# RSL15 register map
Vendor: ONSemiconductor; Series: RSL15 Series; File version: 1.0
CPU: CM33 r0p4, little endian, MPU, FPU, 3 interrupt priority bits
Registers are 32-bit, read-write, reset 0x0 unless marked. A register's access mark holds for its fields unless they carry their own. Offsets are from the block's base; [hi:lo] are bit positions; 'fields as' and 'values as' point back to an identical list.

## RF0 (part 2 of 3) — RF Front-End 2.4 GHz
Base 0x40040800
Same registers: RF1 0x40040A00, RF2 0x40040C00
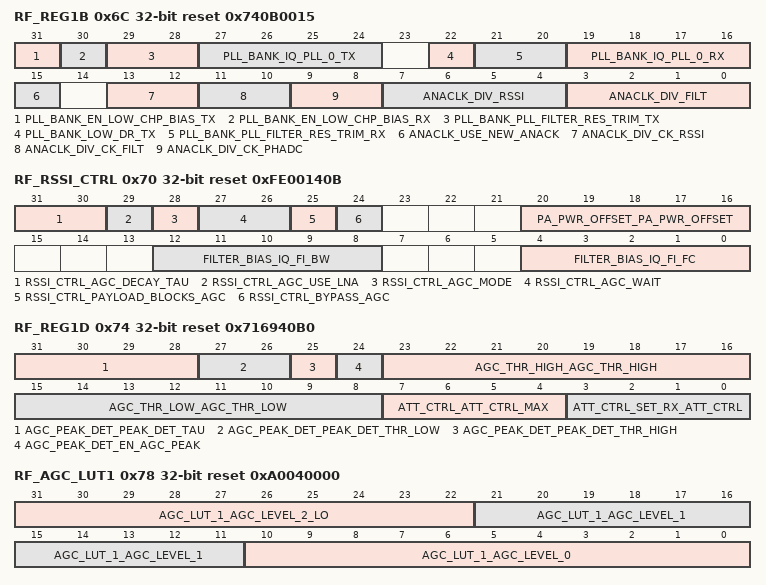
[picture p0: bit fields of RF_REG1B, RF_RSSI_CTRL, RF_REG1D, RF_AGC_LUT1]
0x6C RF_REG1B reset 0x740B0015 — REG1B
  [31] PLL_BANK_EN_LOW_CHP_BIAS_TX — Set the en_low_chp_bias bit in Tx mode (banked)
    0=PLL_BANK_EN_LOW_CHP_BIAS_TX_RESET (In Tx mode EN_LOW_CHP_BIAS bit is reset); 1=PLL_BANK_EN_LOW_CHP_BIAS_TX_SET (In Tx mode EN_LOW_CHP_BIAS bit is set)
  [30] PLL_BANK_EN_LOW_CHP_BIAS_RX — Set the en_low_chp_bias bit in Rx mode (banked)
    0=PLL_BANK_EN_LOW_CHP_BIAS_RX_RESET (In Rx mode EN_LOW_CHP_BIAS bit is reset); 1=PLL_BANK_EN_LOW_CHP_BIAS_RX_SET (In Rx mode EN_LOW_CHP_BIAS bit is set)
  [29:28] PLL_BANK_PLL_FILTER_RES_TRIM_TX — Modify the value of the loop filter resistor R2 when bit 5 is high in Tx mode (banked)
    0=Normal resistor; 1=Normal resistor + 23 percent; 2=Normal resistor + 30 percent; 3=Normal resistor + 70 percent
  [27:24] PLL_BANK_IQ_PLL_0_TX — Charge pump bias for Tx case (banked)
    4=PLL_BANK_IQ_PLL_0_TX_DEFAULT
  [22] PLL_BANK_LOW_DR_TX — Enable low data-rate mode in Tx mode (banked)
    0=PLL_BANK_LOW_DR_TX_DISABLE (Tx works not in low data rate); 1=PLL_BANK_LOW_DR_TX_ENABLE (Tx works in low data rate)
  [21:20] PLL_BANK_PLL_FILTER_RES_TRIM_RX — Modify the value of the loop filter resistor R2 when bit 5 is high in Rx mode (banked)
    values as PLL_BANK_PLL_FILTER_RES_TRIM_TX
  [19:16] PLL_BANK_IQ_PLL_0_RX — Charge pump bias for Rx (banked)
    11=PLL_BANK_IQ_PLL_0_RX_DEFAULT
  [15] ANACLK_USE_NEW_ANACK — Use the new analog clock generator (banked)
    0=ANACLK_USE_NEW_ANACK_DISABLE (Do not use the analog clock generator); 1=ANACLK_USE_NEW_ANACK_ENABLE (Use the analog clock generator)
  [13:12] ANACLK_DIV_CK_RSSI — Set the master clock divider for the RSSI clock (banked)
    0=Division by 3; 1=Division by 2; 2=Division by 1
  [11:10] ANACLK_DIV_CK_FILT — Set the master clock divider for the channel filter clock (banked)
    0=Division by 3; 1=Division by 2; 2=Division by 1
  [9:8] ANACLK_DIV_CK_PHADC — Set the master clock divider for the phase ADC clock (banked)
    0=Division by 3; 1=Division by 2; 2=Division by 1
  [7:4] ANACLK_DIV_RSSI — Unsigned value that specifies the division factor for the clock controlling the RSSI (banked)
    1=ANACLK_DIV_RSSI_DEFAULT
  [3:0] ANACLK_DIV_FILT — Unsigned value that specifies the division factor for the clock controlling the channel filter (banked)
    5=ANACLK_DIV_FILT_DEFAULT
0x70 RF_RSSI_CTRL reset 0xFE00140B — RSSI_CTRL
  [31:30] RSSI_CTRL_AGC_DECAY_TAU — Time constant of the decay speed
    3=RSSI_CTRL_AGC_DECAY_TAU_DEFAULT (High values corresponds to a slow decay)
  [29] RSSI_CTRL_AGC_USE_LNA — AGC algorithm uses LNA bias
    0=RSSI_CTRL_AGC_USE_LNA_DISABLE (AGC algorithm doesn't use the LNA bias); 1=RSSI_CTRL_AGC_USE_LNA_ENABLE (AGC algorithm uses the LNA bias)
  [28] RSSI_CTRL_AGC_MODE — AGC algorithm selection
    0=RSSI_CTRL_AGC_MODE_DISABLE (Old AGC algorithm); 1=RSSI_CTRL_AGC_MODE_ENABLE (New AGC algorithm)
  [27:26] RSSI_CTRL_AGC_WAIT — Set the wait time of the AGC after switching between state
    0=Don't wait; 1=Wait 1x RSSI filtering period; 2=Wait 2x RSSI filtering period; 3=Wait 3x RSSI filtering period
  [25] RSSI_CTRL_PAYLOAD_BLOCKS_AGC — AGC payload blocking
    0=RSSI_CTRL_PAYLOAD_BLOCKS_AGC_DISABLE (AGC is not blocked during the payload); 1=RSSI_CTRL_PAYLOAD_BLOCKS_AGC_ENABLE (AGC is blocked during the payload)
  [24] RSSI_CTRL_BYPASS_AGC — AGC algorithm bypass
    0=RSSI_CTRL_BYPASS_AGC_DISABLE (AGC algorithm is not bypassed); 1=RSSI_CTRL_BYPASS_AGC_ENABLE (AGC algorithm is bypassed)
  [20:16] PA_PWR_OFFSET_PA_PWR_OFFSET — Signed value that sets the PA power (banked)
    0=PA_PWR_OFFSET_PA_PWR_OFFSET_DEFAULT
  [12:8] FILTER_BIAS_IQ_FI_BW — Bias for the bandwidth of the channel filter (banked)
    20=FILTER_BIAS_IQ_FI_BW_DEFAULT
  [4:0] FILTER_BIAS_IQ_FI_FC — Bias for the central frequency of the channel filter (banked)
    11=FILTER_BIAS_IQ_FI_FC_DEFAULT
0x74 RF_REG1D reset 0x716940B0 — REG1D
  [31:28] AGC_PEAK_DET_PEAK_DET_TAU — Time constant of the peak detector monostable circuit
    7=AGC_PEAK_DET_PEAK_DET_TAU_DEFAULT
  [27:26] AGC_PEAK_DET_PEAK_DET_THR_LOW — Threshold for the low level of the peak detector
    0=AGC_PEAK_DET_PEAK_DET_THR_LOW_DEFAULT (0 => 0, 1 => 1, 2 => 2, 3 => N.A.)
  [25] AGC_PEAK_DET_PEAK_DET_THR_HIGH — Threshold for the high level of the peak detector
    0=Threshold 2 for the high level of the peak detector; 1=Threshold 3 for the high level of the peak detector
  [24] AGC_PEAK_DET_EN_AGC_PEAK — Enable AGC peak detector
    0=AGC_PEAK_DET_EN_AGC_PEAK_DISABLE (Disable the AGC peak detector); 1=AGC_PEAK_DET_EN_AGC_PEAK_ENABLE (Enable the AGC peak detector)
  [23:16] AGC_THR_HIGH_AGC_THR_HIGH — AGC threshold high level (banked)
    105=AGC_THR_HIGH_AGC_THR_HIGH_DEFAULT
  [15:8] AGC_THR_LOW_AGC_THR_LOW — AGC threshold low level (banked)
    64=AGC_THR_LOW_AGC_THR_LOW_DEFAULT
  [7:4] ATT_CTRL_ATT_CTRL_MAX — Maximum attenuation level in AGC algorithm
    11=ATT_CTRL_ATT_CTRL_MAX_DEFAULT
  [3:0] ATT_CTRL_SET_RX_ATT_CTRL — Attenuation level if the AGC is bypassed
    0=ATT_CTRL_SET_RX_ATT_CTRL_DEFAULT
0x78 RF_AGC_LUT1 reset 0xA0040000 — AGC_LUT1
  [31:22] AGC_LUT_1_AGC_LEVEL_2_LO — AGC values level 2 (LSB)
    0x280=AGC_LUT_1_AGC_LEVEL_2_LO_DEFAULT
  [21:11] AGC_LUT_1_AGC_LEVEL_1 — AGC values level 1
    128=AGC_LUT_1_AGC_LEVEL_1_DEFAULT
  [10:0] AGC_LUT_1_AGC_LEVEL_0 — AGC values level 0
    0=AGC_LUT_1_AGC_LEVEL_0_DEFAULT
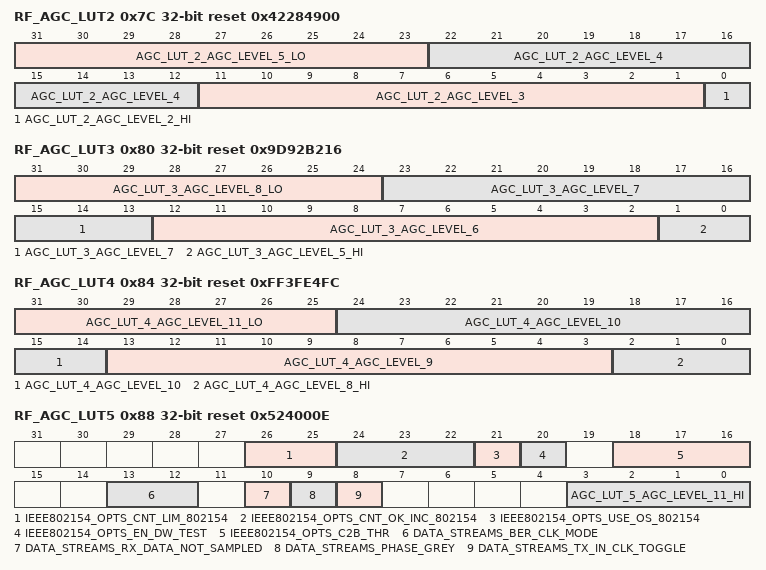
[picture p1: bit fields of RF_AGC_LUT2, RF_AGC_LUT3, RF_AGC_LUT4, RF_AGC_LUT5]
0x7C RF_AGC_LUT2 reset 0x42284900 — AGC_LUT2
  [31:23] AGC_LUT_2_AGC_LEVEL_5_LO — AGC values level 5 (LSB)
    132=AGC_LUT_2_AGC_LEVEL_5_LO_DEFAULT
  [22:12] AGC_LUT_2_AGC_LEVEL_4 — AGC values level 4
    0x284=AGC_LUT_2_AGC_LEVEL_4_DEFAULT
  [11:1] AGC_LUT_2_AGC_LEVEL_3 — AGC values level 3
    0x480=AGC_LUT_2_AGC_LEVEL_3_DEFAULT
  [0] AGC_LUT_2_AGC_LEVEL_2_HI — AGC values level 2 (MSB)
    0=AGC_LUT_2_AGC_LEVEL_2_HI_DEFAULT
0x80 RF_AGC_LUT3 reset 0x9D92B216 — AGC_LUT3
  [31:24] AGC_LUT_3_AGC_LEVEL_8_LO — AGC values level 8 (LSB)
    157=AGC_LUT_3_AGC_LEVEL_8_LO_DEFAULT
  [23:13] AGC_LUT_3_AGC_LEVEL_7 — AGC values level 7
    0x495=AGC_LUT_3_AGC_LEVEL_7_DEFAULT
  [12:2] AGC_LUT_3_AGC_LEVEL_6 — AGC values level 6
    0x485=AGC_LUT_3_AGC_LEVEL_6_DEFAULT
  [1:0] AGC_LUT_3_AGC_LEVEL_5_HI — AGC values level 5 (MSB)
    2=AGC_LUT_3_AGC_LEVEL_5_HI_DEFAULT
0x84 RF_AGC_LUT4 reset 0xFF3FE4FC — AGC_LUT4
  [31:25] AGC_LUT_4_AGC_LEVEL_11_LO — AGC values level 11 (LSB)
    127=AGC_LUT_4_AGC_LEVEL_11_LO_DEFAULT
  [24:14] AGC_LUT_4_AGC_LEVEL_10 — AGC values level 10
    0x4FF=AGC_LUT_4_AGC_LEVEL_10_DEFAULT
  [13:3] AGC_LUT_4_AGC_LEVEL_9 — AGC values level 9
    0x49F=AGC_LUT_4_AGC_LEVEL_9_DEFAULT
  [2:0] AGC_LUT_4_AGC_LEVEL_8_HI — AGC values level 8 (MSB)
    4=AGC_LUT_4_AGC_LEVEL_8_HI_DEFAULT
0x88 RF_AGC_LUT5 reset 0x524000E — AGC_LUT5
  [26:25] IEEE802154_OPTS_CNT_LIM_802154 — Set the number of samples to wait before increasing the threshold
    2=IEEE802154_OPTS_CNT_LIM_802154_DEFAULT
  [24:22] IEEE802154_OPTS_CNT_OK_INC_802154 — Set the increment to the counter that indicates that the correlators peaks are coherent
    4=IEEE802154_OPTS_CNT_OK_INC_802154_DEFAULT
  [21] IEEE802154_OPTS_USE_OS_802154 — Enable the new algorithm working in the oversampled domain for the demodulation of the IEEE 802.15.4 protocol
    0=IEEE802154_OPTS_USE_OS_802154_DISABLE (Disable the Tx data-whitening); 1=IEEE802154_OPTS_USE_OS_802154_ENABLE (Enable the Tx data-whitening)
  [20] IEEE802154_OPTS_EN_DW_TEST — Tx data-whitening before the convolutional code block
    0=IEEE802154_OPTS_EN_DW_TEST_DISABLE (Disable the Tx data-whitening); 1=IEEE802154_OPTS_EN_DW_TEST_ENABLE (Enable the Tx data-whitening)
  [18:16] IEEE802154_OPTS_C2B_THR — Threshold of the chip2bit correlator of the IEEE 802.15.4 protocol
    4=IEEE802154_OPTS_C2B_THR_DEFAULT
  [13:12] DATA_STREAMS_BER_CLK_MODE — Set the clock output mode for BER mode or RW mode
    0=DATA_STREAMS_BER_CLK_MODE_FALLING (data change on falling edge); 1=DATA_STREAMS_BER_CLK_MODE_RISING (Data change on rising edge); 2=DATA_STREAMS_BER_CLK_MODE_TOGGLE (Clock signal is a toggled signal); 3=DATA_STREAMS_BER_CLK_MODE_RECOVERY (Enable signal from clock recovery)
  [10] DATA_STREAMS_RX_DATA_NOT_SAMPLED — Signal rx_data in test modes sampling
    0=DATA_STREAMS_RX_DATA_NOT_SAMPLED_DISABLE (The signal rx_data in test modes is sampled); 1=DATA_STREAMS_RX_DATA_NOT_SAMPLED_ENABLE (The signal rx_data in test modes is not sampled)
  [9] DATA_STREAMS_PHASE_GREY — Phase signal encoding
    0=DATA_STREAMS_PHASE_GREY_DISABLE (The phase signal on the test bus is not grey encoded); 1=DATA_STREAMS_PHASE_GREY_ENABLE (The phase signal on the test bus is grey encoded)
  [8] DATA_STREAMS_TX_IN_CLK_TOGGLE — Input clock
    0=DATA_STREAMS_TX_IN_CLK_TOGGLE_DISABLE (Input clock is not a toggling signal); 1=DATA_STREAMS_TX_IN_CLK_TOGGLE_ENABLE (input clock is a toggling signal)
  [3:0] AGC_LUT_5_AGC_LEVEL_11_HI — AGC values level 11 (MSB)
    14=AGC_LUT_5_AGC_LEVEL_11_HI_DEFAULT
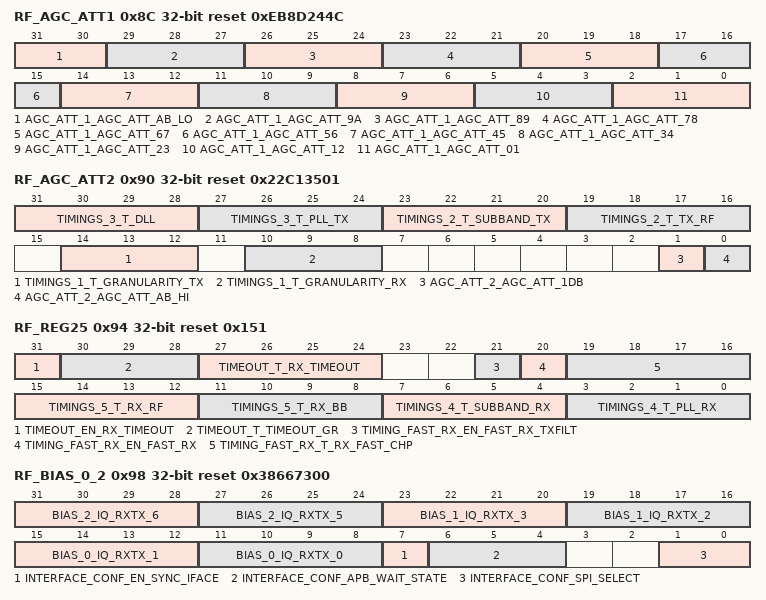
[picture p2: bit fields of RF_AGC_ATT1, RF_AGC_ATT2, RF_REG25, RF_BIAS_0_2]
0x8C RF_AGC_ATT1 reset 0xEB8D244C — AGC_ATT1
  [31:30] AGC_ATT_1_AGC_ATT_AB_LO — AGC attenuation step 10/11 (LSB)
    3=AGC_ATT_1_AGC_ATT_AB_LO_DEFAULT
  [29:27] AGC_ATT_1_AGC_ATT_9A — AGC attenuation step 9/10
    5=AGC_ATT_1_AGC_ATT_9A_DEFAULT
  [26:24] AGC_ATT_1_AGC_ATT_89 — AGC attenuation step 8/9
    3=AGC_ATT_1_AGC_ATT_89_DEFAULT
  [23:21] AGC_ATT_1_AGC_ATT_78 — AGC attenuation step 7/8
    4=AGC_ATT_1_AGC_ATT_78_DEFAULT
  [20:18] AGC_ATT_1_AGC_ATT_67 — AGC attenuation step 6/7
    3=AGC_ATT_1_AGC_ATT_67_DEFAULT
  [17:15] AGC_ATT_1_AGC_ATT_56 — AGC attenuation step 5/6
    2=AGC_ATT_1_AGC_ATT_56_DEFAULT
  [14:12] AGC_ATT_1_AGC_ATT_45 — AGC attenuation step 4/5
    2=AGC_ATT_1_AGC_ATT_45_DEFAULT
  [11:9] AGC_ATT_1_AGC_ATT_34 — AGC attenuation step 3/4
    2=AGC_ATT_1_AGC_ATT_34_DEFAULT
  [8:6] AGC_ATT_1_AGC_ATT_23 — AGC attenuation step 2/3
    1=AGC_ATT_1_AGC_ATT_23_DEFAULT
  [5:3] AGC_ATT_1_AGC_ATT_12 — AGC attenuation step 1/2
    1=AGC_ATT_1_AGC_ATT_12_DEFAULT
  [2:0] AGC_ATT_1_AGC_ATT_01 — AGC attenuation step 0/1
    4=AGC_ATT_1_AGC_ATT_01_DEFAULT
0x90 RF_AGC_ATT2 reset 0x22C13501 — AGC_ATT2
  [31:28] TIMINGS_3_T_DLL — Time needed by the DLL blocks to switch on
    2=TIMINGS_3_T_DLL_DEFAULT
  [27:24] TIMINGS_3_T_PLL_TX — Time needed by the PLL blocks in Tx mode to switch on
    2=TIMINGS_3_T_PLL_TX_DEFAULT
  [23:20] TIMINGS_2_T_SUBBAND_TX — Time needed by the subband algorithm to calibrate in Tx mode
    12=TIMINGS_2_T_SUBBAND_TX_DEFAULT
  [19:16] TIMINGS_2_T_TX_RF — Time needed by the RF blocks to switch on in Tx mode
    1=TIMINGS_2_T_TX_RF_DEFAULT
  [14:12] TIMINGS_1_T_GRANULARITY_TX — Define the granularity of the timer in Tx mode
    3=TIMINGS_1_T_GRANULARITY_TX_DEFAULT (The granularity is given by (2^(t_granularity-2)) x 1us)
  [10:8] TIMINGS_1_T_GRANULARITY_RX — Define the granularity of the timer in Rx mode
    5=TIMINGS_1_T_GRANULARITY_RX_DEFAULT (The granularity is given by (2^(t_granularity)) x 1us))
  [1] AGC_ATT_2_AGC_ATT_1DB — Attenuation steps
    0=AGC_ATT_2_AGC_ATT_1DB_DISABLE (Attenuation is not specified by 1dB steps from 4dB to 11dB); 1=AGC_ATT_2_AGC_ATT_1DB_ENABLE (Attenuation is specified by 1dB steps from 4dB to 11dB)
  [0] AGC_ATT_2_AGC_ATT_AB_HI — AGC attenuation step 10/11 (MSB)
    0=AGC_ATT_2_AGC_ATT_AB_HI_DISABLE (AGC_ATT_2_AGC_ATT_AB MSB is 0); 1=AGC_ATT_2_AGC_ATT_AB_HI_ENABLE (AGC_ATT_2_AGC_ATT_AB MSB is 1)
0x94 RF_REG25 reset 0x151 — REG25
  [31] TIMEOUT_EN_RX_TIMEOUT — Timeout of the Rx when the system is on FSM mode
    0=TIMEOUT_EN_RX_TIMEOUT_DISABLE (Disable the timeout of the Rx); 1=TIMEOUT_EN_RX_TIMEOUT_ENABLE (Enable the timeout of the Rx)
  [30:28] TIMEOUT_T_TIMEOUT_GR — Granularity of the timer in timeout Rx mode
    0=TIMEOUT_T_TIMEOUT_GR_DEFAULT
  [27:24] TIMEOUT_T_RX_TIMEOUT — Time that has to occur before the timeout
    0=TIMEOUT_T_RX_TIMEOUT_DEFAULT
  [21] TIMING_FAST_RX_EN_FAST_RX_TXFILT — Filter Tx configuration for the fast Rx PLL
    0=TIMING_FAST_RX_EN_FAST_RX_TXFILT_DISABLE (Disable filter Tx configuration for the fast Rx PLL); 1=TIMING_FAST_RX_EN_FAST_RX_TXFILT_ENABLE (Enable filter Tx configuration for the fast Rx PLL)
  [20] TIMING_FAST_RX_EN_FAST_RX — Fast Rx PLL
    0=TIMING_FAST_RX_EN_FAST_RX_DISABLE (Disable the fast Rx PLL); 1=TIMING_FAST_RX_EN_FAST_RX_ENABLE (Enable the fast Rx PLL)
  [19:16] TIMING_FAST_RX_T_RX_FAST_CHP — Time to switch off the fast CHP in Rx mode
    0=TIMING_FAST_RX_T_RX_FAST_CHP_DEFAULT
  [15:12] TIMINGS_5_T_RX_RF — Time needed by the RF blocks to switch on in Rx mode
    0=TIMINGS_5_T_RX_RF_DEFAULT
  [11:8] TIMINGS_5_T_RX_BB — Time needed by the BB blocks to switch on in Rx mode
    1=TIMINGS_5_T_RX_BB_DEFAULT
  [7:4] TIMINGS_4_T_SUBBAND_RX — Time needed by the subband algorithm to calibrate in Rx mode
    5=TIMINGS_4_T_SUBBAND_RX_DEFAULT
  [3:0] TIMINGS_4_T_PLL_RX — Time needed by the PLL blocks to switch on in Rx mode
    1=TIMINGS_4_T_PLL_RX_DEFAULT
0x98 RF_BIAS_0_2 reset 0x38667300 — BIAS_0_2
  [31:28] BIAS_2_IQ_RXTX_6 — VCOM_MX bias
    3=BIAS_2_IQ_RXTX_6_DEFAULT
  [27:24] BIAS_2_IQ_RXTX_5 — VCOM_LO bias
    8=BIAS_2_IQ_RXTX_5_DEFAULT
  [23:20] BIAS_1_IQ_RXTX_3 — PrePA Casc bias
    6=BIAS_1_IQ_RXTX_3_DEFAULT
  [19:16] BIAS_1_IQ_RXTX_2 — PrePA In bias
    6=BIAS_1_IQ_RXTX_2_DEFAULT
  [15:12] BIAS_0_IQ_RXTX_1 — PA backoff bias
    7=BIAS_0_IQ_RXTX_1_DEFAULT
  [11:8] BIAS_0_IQ_RXTX_0 — PA bias
    3=BIAS_0_IQ_RXTX_0_DEFAULT
  [7] INTERFACE_CONF_EN_SYNC_IFACE — Interfaces resynchronization
    0=INTERFACE_CONF_EN_SYNC_IFACE_DISABLE (Interfaces are not resynchronized if the clock is available); 1=INTERFACE_CONF_EN_SYNC_IFACE_ENABLE (Interfaces are resynchronized if the clock is available)
  [6:4] INTERFACE_CONF_APB_WAIT_STATE — Select the number of wait states during the APB transaction
    0=INTERFACE_CONF_APB_WAIT_STATE_DEFAULT
  [1:0] INTERFACE_CONF_SPI_SELECT — Select the SPI mode
    0=INTERFACE_CONF_SPI_SELECT_LEGACY_SPI (Legacy SPI); 1=INTERFACE_CONF_SPI_SELECT_ADVANCED_SPI (Advanced SPI); 2=INTERFACE_CONF_SPI_SELECT_BLIM4SME_SPI (BLIM4SME SPI)
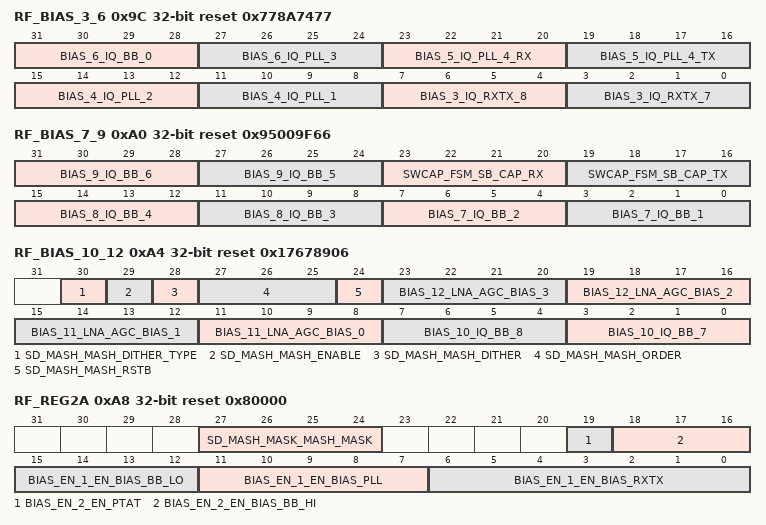
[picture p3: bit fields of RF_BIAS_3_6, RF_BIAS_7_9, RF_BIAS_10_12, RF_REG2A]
0x9C RF_BIAS_3_6 reset 0x778A7477 — BIAS_3_6
  [31:28] BIAS_6_IQ_BB_0 — ACD_O bias
    7=BIAS_6_IQ_BB_0_DEFAULT
  [27:24] BIAS_6_IQ_PLL_3 — DLL bias
    7=BIAS_6_IQ_PLL_3_DEFAULT
  [23:20] BIAS_5_IQ_PLL_4_RX — VCO bias for Rx mode
    8=BIAS_5_IQ_PLL_4_RX_DEFAULT
  [19:16] BIAS_5_IQ_PLL_4_TX — VCO bias for Tx mode
    10=BIAS_5_IQ_PLL_4_TX_DEFAULT
  [15:12] BIAS_4_IQ_PLL_2 — Sub-band comparator bias
    7=BIAS_4_IQ_PLL_2_DEFAULT
  [11:8] BIAS_4_IQ_PLL_1 — Dynamic divider bias
    4=BIAS_4_IQ_PLL_1_DEFAULT
  [7:4] BIAS_3_IQ_RXTX_8 — IFA ctrl_c bias
    7=BIAS_3_IQ_RXTX_8_DEFAULT
  [3:0] BIAS_3_IQ_RXTX_7 — IFA ctrl_r bias
    7=BIAS_3_IQ_RXTX_7_DEFAULT
0xA0 RF_BIAS_7_9 reset 0x95009F66 — BIAS_7_9
  [31:28] BIAS_9_IQ_BB_6 — Peak detector threshold bias 0
    9=BIAS_9_IQ_BB_6_DEFAULT
  [27:24] BIAS_9_IQ_BB_5 — Peak detector bias
    5=BIAS_9_IQ_BB_5_DEFAULT
  [23:20] SWCAP_FSM_SB_CAP_RX — VCO subband selection (FSM in Rx mode)
    0=SWCAP_FSM_SB_CAP_RX_DEFAULT
  [19:16] SWCAP_FSM_SB_CAP_TX — VCO subband selection (FSM in Tx mode)
    0=SWCAP_FSM_SB_CAP_TX_DEFAULT
  [15:12] BIAS_8_IQ_BB_4 — RSSI_D bias
    9=BIAS_8_IQ_BB_4_DEFAULT
  [11:8] BIAS_8_IQ_BB_3 — RSSI_G bias
    15=BIAS_8_IQ_BB_3_DEFAULT
  [7:4] BIAS_7_IQ_BB_2 — ACD_L bias
    6=BIAS_7_IQ_BB_2_DEFAULT
  [3:0] BIAS_7_IQ_BB_1 — ACD_C bias
    6=BIAS_7_IQ_BB_1_DEFAULT
0xA4 RF_BIAS_10_12 reset 0x17678906 — BIAS_10_12
  [30] SD_MASH_MASH_DITHER_TYPE — Enable the new dithering scheme
    0=Disable the new dithering scheme; 1=SD_MASH_MASH_DITHER_TYPE_ENABLE (Enable the new dithering scheme)
  [29] SD_MASH_MASH_ENABLE — Enable the sigma delta mash
    0=SD_MASH_MASH_ENABLE_DISABLE (Disable the sigma delta mash); 1=SD_MASH_MASH_ENABLE_ENABLE (Enable the sigma delta mash)
  [28] SD_MASH_MASH_DITHER — Enable dithering on the sigma delta mash
    0=SD_MASH_MASH_DITHER_DISABLE (Disable dithering on the sigma delta mash); 1=SD_MASH_MASH_DITHER_ENABLE (Enable dithering on the sigma delta mash)
  [27:25] SD_MASH_MASH_ORDER — Order of the sigma delta mash
    3=SD_MASH_MASH_ORDER_DEFAULT
  [24] SD_MASH_MASH_RSTB — Reset of the sigma delta mash (active low)
    0=SD_MASH_MASH_RSTB_RESET (Reset the sigma delta mash); 1=SD_MASH_MASH_RSTB_NO_RESET (Do not reset the sigma delta mash)
  [23:20] BIAS_12_LNA_AGC_BIAS_3 — LNA bias for AGC level 3
    6=BIAS_12_LNA_AGC_BIAS_3_DEFAULT
  [19:16] BIAS_12_LNA_AGC_BIAS_2 — LNA bias for AGC level 2
    7=BIAS_12_LNA_AGC_BIAS_2_DEFAULT
  [15:12] BIAS_11_LNA_AGC_BIAS_1 — LNA bias for AGC level 1
    8=BIAS_11_LNA_AGC_BIAS_1_DEFAULT
  [11:8] BIAS_11_LNA_AGC_BIAS_0 — LNA bias for AGC level 0
    9=BIAS_11_LNA_AGC_BIAS_0_DEFAULT
  [7:4] BIAS_10_IQ_BB_8 — Peak detector threshold bias 1
    0=BIAS_10_IQ_BB_8_DEFAULT
  [3:0] BIAS_10_IQ_BB_7 — Peak detector threshold bias 2
    6=BIAS_10_IQ_BB_7_DEFAULT
0xA8 RF_REG2A reset 0x80000 — REG2A
  [27:24] SD_MASH_MASK_MASH_MASK — Mask the n LSB of the fractional part of the MASH (debug only)
    0=SD_MASH_MASK_MASH_MASK_DEFAULT
  [19] BIAS_EN_2_EN_PTAT — Enable PTAT
    0=BIAS_EN_2_EN_PTAT_DISABLE (Disable PTAT); 1=BIAS_EN_2_EN_PTAT_ENABLE (Enable PTAT)
  [18:16] BIAS_EN_2_EN_BIAS_BB_HI — Bias enable for BB (same order as biases)
    0=BIAS_EN_2_EN_BIAS_BB_HI_DEFAULT
  [15:12] BIAS_EN_1_EN_BIAS_BB_LO — Bias enable for BB (same order as biases)
    0=BIAS_EN_1_EN_BIAS_BB_LO_DEFAULT
  [11:7] BIAS_EN_1_EN_BIAS_PLL — Bias enable for PLL (same order as biases)
    0=BIAS_EN_1_EN_BIAS_PLL_DEFAULT
  [6:0] BIAS_EN_1_EN_BIAS_RXTX — Bias enable for RxTx (same order as biases)
    0=BIAS_EN_1_EN_BIAS_RXTX_DEFAULT
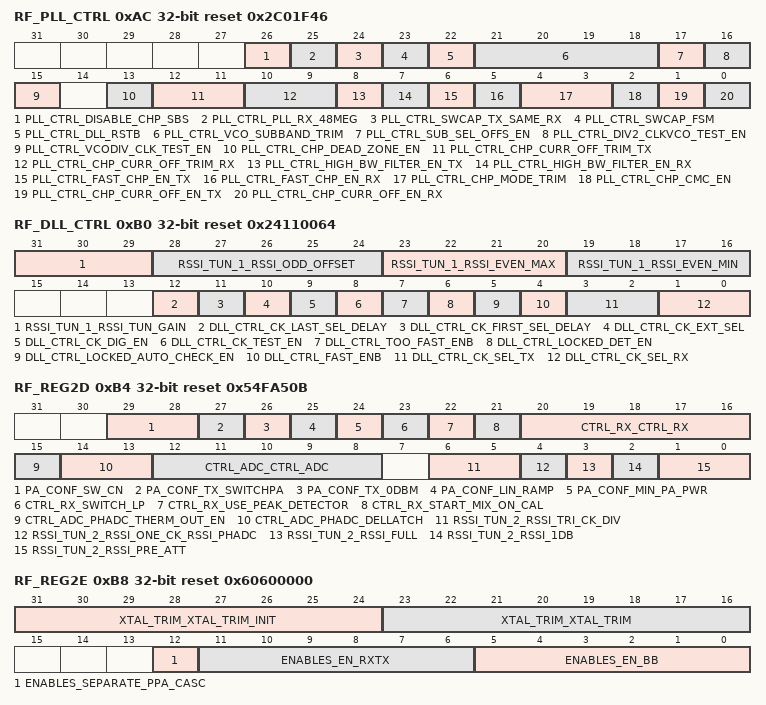
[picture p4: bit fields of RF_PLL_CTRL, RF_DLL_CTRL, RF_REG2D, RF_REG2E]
0xAC RF_PLL_CTRL reset 0x2C01F46 — PLL_CTRL
  [26] PLL_CTRL_DISABLE_CHP_SBS — Charge-pump disabling during sub-band selection (FLL and frequency ratios)
    0=PLL_CTRL_2_DISABLE_CHP_SBS_DISABLE (Charge-pump is enabled during the sub-band selection); 1=PLL_CTRL_2_DISABLE_CHP_SBS_ENABLE (Charge-pump is disabled during the sub-band selection)
  [25] PLL_CTRL_PLL_RX_48MEG — PLL frequency
    0=PLL_CTRL_2_PLL_RX_48MEG_24 (PLL is set to 24MHz in Rx); 1=PLL_CTRL_2_PLL_RX_48MEG_48 (PLL is set to 48MHz in Rx)
  [24] PLL_CTRL_SWCAP_TX_SAME_RX — Registers for Rx and Tx modes swcap in case of swcap_fsm=1
    0=PLL_CTRL_2_SWCAP_TX_SAME_RX_DISABLE (The register for Rx and Tx swcap is not the same); 1=PLL_CTRL_2_SWCAP_TX_SAME_RX_ENABLE (The register for Rx and Tx swcap is the same)
  [23] PLL_CTRL_SWCAP_FSM — Selection of the swcap_fsm register
    0=PLL_CTRL_2_SWCAP_FSM_DISABLE (Don't use the swcap_fsm register as reference for the sub-band selection); 1=PLL_CTRL_2_SWCAP_FSM_ENABLE (Use the swcap_fsm register as reference for the sub-band selection)
  [22] PLL_CTRL_DLL_RSTB — Reset signal of the DLL (active low)
    0=PLL_CTRL_2_DLL_RSTB_RESET (Reset the DLL); 1=PLL_CTRL_2_DLL_RSTB_NO_RESET (Don't reset the DLL)
  [21:18] PLL_CTRL_VCO_SUBBAND_TRIM — VCO sub-band selection bits
    0=PLL_CTRL_VCO_SUBBAND_TRIM_DEFAULT
  [17] PLL_CTRL_SUB_SEL_OFFS_EN — Add offset to sub-band selection comparator
    0=PLL_CTRL_1_SUB_SEL_OFFS_EN_DISABLE (Don't add offset to sub-band selection comparator); 1=PLL_CTRL_1_SUB_SEL_OFFS_EN_ENABLE (Add offset to sub-band selection comparator)
  [16] PLL_CTRL_DIV2_CLKVCO_TEST_EN — VCO signal divided by the programmable divider
    0=PLL_CTRL_1_DIV2_CLKVCO_TEST_EN_1 (Division ratio set to 1); 1=PLL_CTRL_1_DIV2_CLKVCO_TEST_EN_2 (Division ratio set to 2 (before to be outputted to ck_div_test))
  [15] PLL_CTRL_VCODIV_CLK_TEST_EN — Output on GPIO the VCO signal divided by the programmable divider
    0=PLL_CTRL_1_VCODIV_CLK_TEST_EN_DISABLE (Disable to output on GPIO the VCO signal divided by the programmable divider); 1=PLL_CTRL_ENABLE_VCODIV_CLK_TEST_EN_ENABLE (Enable to output on GPIO the VCO signal divided by the programmable divider)
  [13] PLL_CTRL_CHP_DEAD_ZONE_EN — Charge-pump dead zone
    0=PLL_CTRL_1_CHP_DEAD_ZONE_EN_DISABLE (Disable charge-pump dead zone); 1=PLL_CTRL_ENABLE_CHP_DEAD_ZONE_EN_ENABLE (Enable charge-pump dead zone)
  [12:11] PLL_CTRL_CHP_CURR_OFF_TRIM_TX — Charge-pump offset current values selection bits in Tx mode
    0=PLL_CTRL_1_CHP_CURR_OFF_TRIM_TX_15 (d_phi=15); 1=PLL_CTRL_1_CHP_CURR_OFF_TRIM_TX_22 (d_phi=22.5); 2=PLL_CTRL_1_CHP_CURR_OFF_TRIM_TX_30 (d_phi = 30); 3=PLL_CTRL_1_CHP_CURR_OFF_TRIM_TX_60 (d_phi = 60)
  [10:9] PLL_CTRL_CHP_CURR_OFF_TRIM_RX — Charge-pump offset current values selection bits in Rx mode
    0=PLL_CTRL_1_CHP_CURR_OFF_TRIM_RX_15 (d_phi=15); 1=PLL_CTRL_1_CHP_CURR_OFF_TRIM_RX_22 (d_phi=22.5); 2=PLL_CTRL_1_CHP_CURR_OFF_TRIM_RX_30 (d_phi = 30); 3=PLL_CTRL_1_CHP_CURR_OFF_TRIM_RX_60 (d_phi = 60)
  [8] PLL_CTRL_HIGH_BW_FILTER_EN_TX — PLL filter high bandwidth needed in Tx mode
    0=PLL_CTRL_HIGH_BW_FILTER_EN_TX_DISABLE (Disable the PLL filter high bandwidth needed in TX); 1=PLL_CTRL_HIGH_BW_FILTER_EN_TX_ENABLE (Enable the PLL filter high bandwidth needed in TX)
  [7] PLL_CTRL_HIGH_BW_FILTER_EN_RX — PLL filter high bandwidth needed in Rx mode
    0=PLL_CTRL_HIGH_BW_FILTER_EN_RX_DISABLE (Disable the PLL filter high bandwidth needed in RX); 1=PLL_CTRL_HIGH_BW_FILTER_EN_RX_ENABLE (Enable the PLL filter high bandwidth needed in RX)
  [6] PLL_CTRL_FAST_CHP_EN_TX — High current output of the charge-pump for PLL Tx high bandwidth mode
    0=PLL_CTRL_FAST_CHP_EN_TX_DISABLE (Disable the high current output of the charge-pump in TX); 1=PLL_CTRL_FAST_CHP_EN_TX_ENABLE (Enable the high current output of the charge-pum in TX)
  [5] PLL_CTRL_FAST_CHP_EN_RX — High current output of the charge-pump for PLL Rx high bandwidth mode
    0=PLL_CTRL_FAST_CHP_EN_RX_DISABLE (Disable the high current output of the charge-pump in RX); 1=PLL_CTRL_FAST_CHP_EN_RX_ENABLE (Enable the high current output of the charge-pump in RX)
  [4:3] PLL_CTRL_CHP_MODE_TRIM — Select the frequency inside sub-band selection
    0=PLL_CTRL_CHP_MODE_TRIM_MIN_FREQ (Minimum frequency inside sub-band selection); 1=PLL_CTRL_CHP_MODE_TRIM_MED_FREQ (Medium frequency inside sub-band selection); 2=PLL_CTRL_CHP_MODE_TRIM_MAX_FREQ (Maximum frequency inside sub-band selection)
  [2] PLL_CTRL_CHP_CMC_EN — Common mode control block of the charge-pump
    0=PLL_CTRL_CHP_CMC_EN_DISABLE (Disable the common mode control block of the charge-pump); 1=PLL_CTRL_CHP_CMC_EN_ENABLE (Enable the common mode control block of the charge-pump)
  [1] PLL_CTRL_CHP_CURR_OFF_EN_TX — Charge-pump offset current in Tx mode
    0=PLL_CTRL_CHP_CURR_OFF_EN_TX_DISABLE (Disable the charge-pump offset current in TX); 1=PLL_CTRL_CHP_CURR_OFF_EN_TX_ENABLE (Enable the charge-pump offset current in TX)
  [0] PLL_CTRL_CHP_CURR_OFF_EN_RX — Charge-pump offset current in Rx mode
    0=PLL_CTRL_CHP_CURR_OFF_EN_RX_DISABLE (Disable the charge-pump offset current in RX); 1=PLL_CTRL_CHP_CURR_OFF_EN_RX_ENABLE (Enable the charge-pump offset current in RX)
0xB0 RF_DLL_CTRL reset 0x24110064 — DLL_CTRL
  [31:29] RSSI_TUN_1_RSSI_TUN_GAIN — RSSI tuning for gain
    1=RSSI_TUN_1_RSSI_TUN_GAIN_DEFAULT
  [28:24] RSSI_TUN_1_RSSI_ODD_OFFSET — RSSI tuning for odd stages (offset to the even triangular wave)
    4=RSSI_TUN_1_RSSI_ODD_OFFSET_DEFAULT
  [23:20] RSSI_TUN_1_RSSI_EVEN_MAX — RSSI tuning for even stages (maximum value of the triangular wave)
    1=RSSI_TUN_1_RSSI_EVEN_MAX_DEFAULT
  [19:16] RSSI_TUN_1_RSSI_EVEN_MIN — RSSI tuning for even stages (minimum value of the triangular wave)
    1=RSSI_TUN_1_RSSI_EVEN_MIN_DEFAULT
  [12] DLL_CTRL_CK_LAST_SEL_DELAY — Last SEL delay
  [11] DLL_CTRL_CK_FIRST_SEL_DELAY — First SEL delay
  [10] DLL_CTRL_CK_EXT_SEL — Input clock selection
    0=DLL_CTRL_CK_EXT_SEL_XTAL (Input clock comes from ck_xtal pin); 1=DLL_CTRL_CK_EXT_SEL_EXT (Input clock comes from ck_ext pin)
  [9] DLL_CTRL_CK_DIG_EN — Alternate ck_dig pin to output the PLL reference clock signal
    0=DLL_CTRL_CK_DIG_EN_NOMINAL (Don't use the alternate ck_dig pin to output the PLL reference clock signal); 1=DLL_CTRL_CK_DIG_EN_ALTERNATE (Use the alternate ck_dig pin to output the PLL reference clock signal)
  [8] DLL_CTRL_CK_TEST_EN — Output on GPIO the PLL reference clock signal via ck_test pin
    0=Don't output on GPIO the PLL reference clock signal via ck_test pin; 1=DLL_CTRL_CK_TEST_EN_ENABLE (Output on GPIO the PLL reference clock signal via ck_test pin)
  [7] DLL_CTRL_TOO_FAST_ENB — Lock range phase detector
    0=DLL_CTRL_TOO_FAST_ENB_DISABLE (Enable auxiliary wide lock range phase detector when fast mode locking is enabled (fast_enb = 0)); 1=DLL_CTRL_TOO_FAST_ENB_ENABLE (The narrow lock range phase detector is enabled and bit 2 (fast_enb) must be high to avoid false frequency lock (slow mode locking))
  [6] DLL_CTRL_LOCKED_DET_EN — Reference frequency multiplier locked detector
    0=DLL_CTRL_LOCKED_DET_EN_DISABLE (Disable reference frequency multiplier locked detector); 1=DLL_CTRL_LOCKED_DET_EN_ENABLE (Enable reference frequency multiplier locked detector)
  [5] DLL_CTRL_LOCKED_AUTO_CHECK_EN — Frequency multiplier is out of lock (usually because some input clocks from ck_xtal or ck_ext are missing)
    0=DLL_CTRL_LOCKED_AUTO_CHECK_EN_DISABLE (Manual reset should be performed via dll_rstb input(see Table 3) to relock the frequency multiplier); 1=DLL_CTRL_LOCKED_AUTO_CHECK_EN_ENABLE (Frequency multiplier will try to lock again automatically)
  [4] DLL_CTRL_FAST_ENB — Disable fast mode locking of the reference frequency multiplier
    0=DLL_CTRL_FAST_ENB_ENABLE (Fast mode locking of the reference frequency multiplier); 1=DLL_CTRL_FAST_ENB_DISABLE
  [3:2] DLL_CTRL_CK_SEL_TX — Selection of the clock used as frequency reference of the PLL in Tx mode (also to ck_test and ck_dig outputs)
    0=ref = ck_xtal ot ck_ext (if bit 8 is high); 1=ref = same as ck_sel = 00 if dll_en = 0, otherwise frequency(ref) = 3x frequency(ck_xtal) or 3x frequency(ck_ext) (if bit 8 is high); 2=ref = same as ck_sel = 01 but output frequency divided by 2 (used in normal RX mode when dll_en = 0); 3=ref = same as ck_sel = 01 but output frequency divided by 5 (used for RX mode with external signal at 132 MHz when dll_en = 0)
  [1:0] DLL_CTRL_CK_SEL_RX — Selection of the clock used as frequency reference of the PLL in Rx mode (also to ck_test and ck_dig outputs)
    values as DLL_CTRL_CK_SEL_TX
0xB4 RF_REG2D reset 0x54FA50B — REG2D
  [29:28] PA_CONF_SW_CN — Harmonic 2 notch tuning
    0=PA_CONF_SW_CN_DEFAULT
  [27] PA_CONF_TX_SWITCHPA — Switch PA
    0=PA_CONF_TX_SWITCHPA_DISABLE (RF Tx timing); 1=PA_CONF_TX_SWITCHPA_ENABLE (Enable the PA only with the digital block)
  [26] PA_CONF_TX_0DBM — Select between PPA and PA
    0=PA_CONF_TX_DISABLEDBM_DISABLE (Only use the PPA is used (-20dBm)); 1=PA_CONF_TX_DISABLEDBM_ENABLE (Enable the PA)
  [25] PA_CONF_LIN_RAMP — PA ramp-up linearization
    0=PA_CONF_LIN_RAMP_DISABLE (Don't linearize the PA ramp-up by having not equal ramp-up step delays); 1=PA_CONF_LIN_RAMP_ENABLE (Linearize the PA ramp-up by having not equal ramp-up step delays)
  [24] PA_CONF_MIN_PA_PWR — Set the minimum power during the PA ramp-up
    0=PA_CONF_MIN_PA_PWR_M3 (The ramp-up starts at -3); 1=PA_CONF_MIN_PA_PWR_M1 (The ramp-up starts at -1)
  [23] CTRL_RX_SWITCH_LP — Switch the low-pass filter in the Rx chain
    0=CTRL_RX_SWITCH_LP_DISABLE (Do not switch the low-pass filter in the Rx chain); 1=CTRL_RX_SWITCH_LP_ENABLE (Switch the low-pass filter in the Rx chain)
  [22] CTRL_RX_USE_PEAK_DETECTOR — Peak detector powering
    0=CTRL_RX_USE_PEAK_DETECTOR_DISABLE (The peak detector is not powered on during the Rx by the FSM); 1=CTRL_RX_USE_PEAK_DETECTOR_ENABLE (The peak detector is powered on during the Rx by the FSM)
  [21] CTRL_RX_START_MIX_ON_CAL — Mixer enabling
    0=CTRL_RX_START_MIX_ON_CAL_DISABLE (The mixer is disabled during the sub-band selection phase); 1=CTRL_RX_START_MIX_ON_CAL_ENABLE (The mixer is enabled during the sub-band selection phase)
  [20:16] CTRL_RX_CTRL_RX — Rx control
    15=CTRL_RX_CTRL_RX_DEFAULT (Rx control)
  [15] CTRL_ADC_PHADC_THERM_OUT_EN — Enable the buffers of phase ADC thermometric code (banked)
    0=CTRL_ADC_PHADC_THERM_OUT_EN_DISABLE (Disable thermometric code); 1=CTRL_ADC_PHADC_THERM_OUT_EN_ENABLE (Enable thermometric code)
  [14:13] CTRL_ADC_PHADC_DELLATCH — Phase ADC delay latch trimming (banked)
    1=CTRL_ADC_PHADC_DELLATCH_DEFAULT
  [12:8] CTRL_ADC_CTRL_ADC — Phase ADC control (banked)
    5=CTRL_ADC_CTRL_ADC_DEFAULT (bits(1:0) => phase ADC reset delay, bits(3:2) phase ADC clock delay, bit(4) phase ADC latch idle)
  [6:5] RSSI_TUN_2_RSSI_TRI_CK_DIV — Speed on the RSSI triangular dithering signal (cf reg RSSI_TUN)
    0=2 RSSI clk periods; 1=4 RSSI clk periods; 2=8 RSSI clk periods; 3=16 RSSI clk periods
  [4] RSSI_TUN_2_RSSI_ONE_CK_RSSI_PHADC — RSSI and phase ADC clocks sharing
    0=RSSI_TUN_2_RSSI_ONE_CK_RSSI_PHADC_DISABLE (RSSI and the phase ADC don't share the same clock); 1=RSSI_TUN_2_RSSI_ONE_CK_RSSI_PHADC_ENABLE (RSSI and the phase ADC share the same clock)
  [3] RSSI_TUN_2_RSSI_FULL — RSSI full scale
    0=RSSI_TUN_2_RSSI_FULL_DISABLE (RSSI full scale is not used); 1=RSSI_TUN_2_RSSI_FULL_ENABLE (RSSI full scale is used (10bits))
  [2] RSSI_TUN_2_RSSI_1DB — LSB resolution
    0=RSSI_TUN_2_RSSI_1DB_0P5 (LSB is 0.5dB); 1=LSB is 1dB
  [1:0] RSSI_TUN_2_RSSI_PRE_ATT — Pre attenuation of the RSSI signal
    3=RSSI_TUN_2_RSSI_PRE_ATT_DEFAULT
0xB8 RF_REG2E reset 0x60600000 — REG2E
  [31:24] XTAL_TRIM_XTAL_TRIM_INIT — Initial trimming of the XTAL
    96=XTAL_TRIM_XTAL_TRIM_INIT_DEFAULT (5MSB thermometric, 3LSB direct)
  [23:16] XTAL_TRIM_XTAL_TRIM — Trimming of the XTAL
    96=XTAL_TRIM_XTAL_TRIM_DEFAULT (5MSB thermometric, 3LSB direct)
  [12] ENABLES_SEPARATE_PPA_CASC — PA cascode bit
    0=ENABLES_SEPARATE_PPA_CASC_DISABLE (Enable PPA cascode bit is dependent of the en PA); 1=ENABLES_SEPARATE_PPA_CASC_ENABLE (Disable PPA cascode bit is independent from the en PA)
  [11:6] ENABLES_EN_RXTX — Enable signals
    0=LNA; 1=LNA; 2=IFA; 3=TX; 4=PA; 5=PPA casc
  [5:0] ENABLES_EN_BB — Enable signals for the BB
    0=Filter,; 1=Filter central frequency bias; 2=Filter bandwidth bias; 3=ADC; 4=RSSI; 5=Peak detector
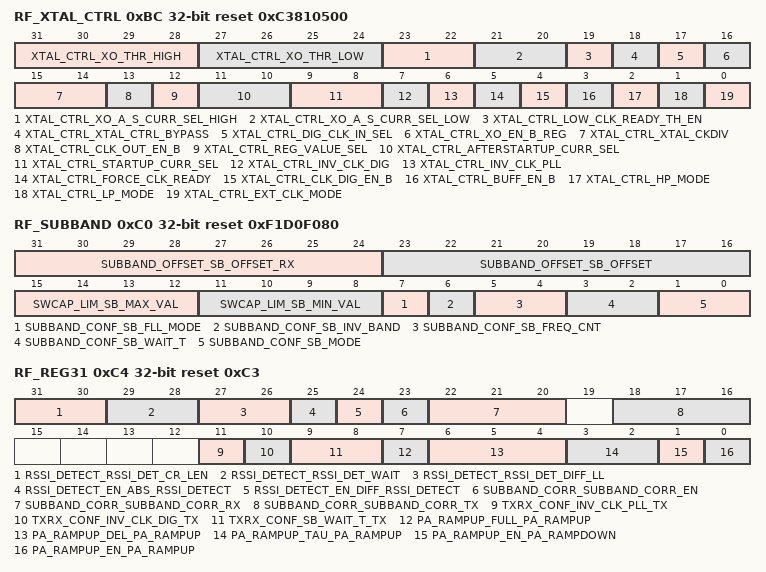
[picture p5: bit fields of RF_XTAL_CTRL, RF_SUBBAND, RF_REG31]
0xBC RF_XTAL_CTRL reset 0xC3810500 — XTAL_CTRL
  [31:28] XTAL_CTRL_XO_THR_HIGH — High threshold for XTAL trimming
    12=XTAL_CTRL_XO_THR_HIGH_DEFAULT
  [27:24] XTAL_CTRL_XO_THR_LOW — Low threshold for XTAL trimming
    3=XTAL_CTRL_XO_THR_LOW_DEFAULT
  [23:22] XTAL_CTRL_XO_A_S_CURR_SEL_HIGH — Value of after_startup_curr_sel when level is higher than xo_thr_high
    2=XTAL_CTRL_XO_A_S_CURR_SEL_HIGH_DEFAULT
  [21:20] XTAL_CTRL_XO_A_S_CURR_SEL_LOW — Value of after_startup_curr_sel when level is lower than xo_thr_low
    0=XTAL_CTRL_XO_A_S_CURR_SEL_LOW_DEFAULT
  [19] XTAL_CTRL_LOW_CLK_READY_TH_EN — clk_ready threshold
    0=XTAL_CTRL_LOW_CLK_READY_TH_EN_NOMINAL (The clk_ready threshold is nominal); 1=XTAL_CTRL_LOW_CLK_READY_TH_EN_LOW (The clk_ready threshold is set to a lower value)
  [18] XTAL_CTRL_XTAL_CTRL_BYPASS — Bypass the XTAL control algorithm
    0=XTAL_CTRL_XTAL_CTRL_BYPASS_DISABLE (Don't bypass the Xtal control algorithm); 1=XTAL_CTRL_XTAL_CTRL_BYPASS_ENABLE (Bypass the Xtal control algorithm)
  [17] XTAL_CTRL_DIG_CLK_IN_SEL — Clock selection for the digital block
    0=XTAL_CTRL_DIG_CLK_IN_SEL_XTAL (Select the internal xtal); 1=XTAL_CTRL_DIG_CLK_IN_SEL_CLK_IN (Select the clk_in_dig signal)
  [16] XTAL_CTRL_XO_EN_B_REG — XTAL oscillator enable
    0=XTAL_CTRL_ENABLE_OSCILLATOR (Xtal oscillator enable); 1=XTAL_CTRL_DISABLE_OSCILLATOR (Xtal oscillator disable)
  [15:14] XTAL_CTRL_XTAL_CKDIV — XTAL trimming speed
    0=43 us; 1=85 us; 2=171 us; 3=341 us
  [13] XTAL_CTRL_CLK_OUT_EN_B — Output clock to go to main IP
    0=XTAL_CTRL_CLK_OUT_EN_B_ENABLE (Enable the output clock to go to main IP); 1=XTAL_CTRL_CLK_OUT_EN_B_DISABLE (Disable the output clock to go to main IP (clk_out output stay low))
  [12] XTAL_CTRL_REG_VALUE_SEL — Control bits of xtal_reg
    0=XTAL_CTRL_REG_VALUE_SEL_EXTERNAL (Main ctrl signals are used instead of corresponding ctrl signal or some control bits of xtal_reg); 1=XTAL_CTRL_REG_VALUE_SEL_INTERNAL (Corresponding ctrl signal and some control bits of xtal_reg are used instead of main ctrl signals.)
  [11:10] XTAL_CTRL_AFTERSTARTUP_CURR_SEL — Selection of the current before amplitude stabilization but after starting-up in active transistors of the core oscillator
    0=0.15 mA; 1=0.24 mA; 2=0.40 mA; 3=0.61 mA
  [9:8] XTAL_CTRL_STARTUP_CURR_SEL — Selection of the starting-up current in active transistors of the core oscillator
    0=0.41 mA; 1=0.59 mA; 2=0.88 mA; 3=1.24 mA
  [7] XTAL_CTRL_INV_CLK_DIG — Invert clock on clk_dig output
    0=XTAL_CTRL_INV_CLK_DIG_DISABLE (Don't invert clock on clk_dig output); 1=XTAL_CTRL_INV_CLK_DIG_ENABLE (Invert clock on clk_dig output)
  [6] XTAL_CTRL_INV_CLK_PLL — Invert clock on clk_pll output
    0=XTAL_CTRL_INV_CLK_PLL_DISABLE (Don't invert clock on clk_pll output); 1=XTAL_CTRL_INV_CLK_PLL_ENABLE (Invert clock on clk_pll output)
  [5] XTAL_CTRL_FORCE_CLK_READY — Force output clocks on clk_pll, clk_dig and clk_out
    0=XTAL_CTRL_FORCE_CLK_READY_DISABLE (Don't force output clocks on clk_pll, clk_dig and clk_out); 1=XTAL_CTRL_FORCE_CLK_READY_ENABLE (Force output clocks on clk_pll, clk_dig and clk_out and bypass the xtal internal clock detector)
  [4] XTAL_CTRL_CLK_DIG_EN_B — Disable the output clock to go to digital (clk_dig output stay low)
    0=XTAL_CTRL_CLK_DIG_EN_B_DISABLE (Enable the output clock to go to digital); 1=XTAL_CTRL_CLK_DIG_EN_B_ENABLE (Disable the output clock to go to digital (clk_dig output stay low))
  [3] XTAL_CTRL_BUFF_EN_B — XTAL buffer disabling
    0=XTAL_CTRL_BUFF_EN_B_DISABLE (The xtal buffer is enabled); 1=XTAL_CTRL_BUFF_EN_B_ENABLE (The xtal buffer is disabled)
  [2] XTAL_CTRL_HP_MODE — Bias current increase in the clock buffer
    0=XTAL_CTRL_HP_MODE_NOMINAL (The bias current in the clock buffer is nominal); 1=XTAL_CTRL_HP_MODE_HIGH (The bias current in the clock buffer is increased)
  [1] XTAL_CTRL_LP_MODE — Bias current decrease in the clock buffer
    0=XTAL_CTRL_LP_MODE_NOMINAL (The bias current in the clock buffer is nominal); 1=XTAL_CTRL_LP_MODE_HIGH (The bias current in the clock buffer is reduced compared to normal operatio)
  [0] XTAL_CTRL_EXT_CLK_MODE — Use XTAL pads as external clock input
    0=XTAL_CTRL_EXT_CLK_MODE_DISABLE (Don not use xtal_p (and eventually xtal_n) as external clock input(s)); 1=XTAL_CTRL_EXT_CLK_MODE_ENABLE (Use xtal_p (and eventually xtal_n) as external clock input(s))
0xC0 RF_SUBBAND reset 0xF1D0F080 — SUBBAND
  [31:24] SUBBAND_OFFSET_SB_OFFSET_RX — Offset to add in frequency count in order to compensate the offset of the varicap
    241=SUBBAND_OFFSET_SB_OFFSET_RX_DEFAULT
  [23:16] SUBBAND_OFFSET_SB_OFFSET — Offset to add in frequency count in order to compensate the offset of the varicap
    208=SUBBAND_OFFSET_SB_OFFSET_DEFAULT
  [15:12] SWCAP_LIM_SB_MAX_VAL — Maximum subband value in linear search subband (freq and comp)
    15=SWCAP_LIM_SB_MAX_VAL_DEFAULT
  [11:8] SWCAP_LIM_SB_MIN_VAL — Minimum subband value in linear search subband (freq and comp)
    0=SWCAP_LIM_SB_MIN_VAL_DEFAULT
  [7] SUBBAND_CONF_SB_FLL_MODE — FLL mode for the subband selection
    0=SUBBAND_CONF_SB_FLL_MODE_DISABLE (Disable the FLL mode for the subband selection); 1=SUBBAND_CONF_SB_FLL_MODE_ENABLE (Enable the FLL mode for the subband selection (overrides other settings))
  [6] SUBBAND_CONF_SB_INV_BAND — Invert the meaning of sb_high and sb_low
    0=SUBBAND_CONF_SB_INV_BAND_DISABLE (Don't invert the meaning of sb_high and sb_low); 1=SUBBAND_CONF_SB_INV_BAND_ENABLE (Invert the meaning of sb_high and sb_low)
  [5:4] SUBBAND_CONF_SB_FREQ_CNT — The length to count in frequency mode
    0=256 (Rx: 10.7us, Tx: 2.13us); 1=512 (Rx: 21.3us, Tx: 4.26us); 2=1024 (Rx: 42.7us, Tx: 8.53us); 3=4096 (Rx: 171us, Tx: 34.1us)
  [3:2] SUBBAND_CONF_SB_WAIT_T — Time to wait to the PLL to settle
    0=Rx 8us, Tx 2us; 1=Rx 12us, Tx 3us; 2=Rx 16us, Tx 4us; 3=Rx 24us, Tx 6u
  [1:0] SUBBAND_CONF_SB_MODE — Sub-band algorithm mode
    0=SAR w/ comparators; 1=linear w/ comparators; 2=SAR w/ frequency ratios; 3=linear w/ frequency ratios
0xC4 RF_REG31 reset 0xC3 — REG31
  [31:30] RSSI_DETECT_RSSI_DET_CR_LEN — Number of samples to estimate the carrier offset (banked)
    0=32 samples; 1=64 samples; 2=128 samples; 3=256 samples
  [29:28] RSSI_DETECT_RSSI_DET_WAIT — Symbols to wait after the RSSI detection (banked)
    0=0 symbol; 1=1 symbol; 2=2 symbols; 3=4 symbols
  [27:26] RSSI_DETECT_RSSI_DET_DIFF_LL — Set the distance between the actual value and the subtracted one (banked)
    0=1 sample; 1=2 samples; 2=3 samples; 3=4 samples
  [25] RSSI_DETECT_EN_ABS_RSSI_DETECT — Absolute RSSI detection (banked)
    0=RSSI_DETECT_EN_ABS_RSSI_DETECT_DISABLE (Disable the absolute RSSI detection); 1=RSSI_DETECT_EN_ABS_RSSI_DETECT_ENABLE (Enable the absolute RSSI detection)
  [24] RSSI_DETECT_EN_DIFF_RSSI_DETECT — Differential RSSI detection (banked)
    0=RSSI_DETECT_EN_DIFF_RSSI_DETECT_DISABLE (Disable the differential RSSI detection); 1=RSSI_DETECT_EN_DIFF_RSSI_DETECT_ENABLE (Enable the differential RSSI detection)
  [23] SUBBAND_CORR_SUBBAND_CORR_EN — Subband correction
    0=SUBBAND_CORR_SUBBAND_CORR_EN_DISABLE (Disable the subband correction); 1=SUBBAND_CORR_SUBBAND_CORR_EN_ENABLE (Enable the subband correction)
  [22:20] SUBBAND_CORR_SUBBAND_CORR_RX — Subband correction in Rx
    0=SUBBAND_CORR_SUBBAND_CORR_RX_DEFAULT
  [18:16] SUBBAND_CORR_SUBBAND_CORR_TX — Subband correction in Tx
    0=SUBBAND_CORR_SUBBAND_CORR_TX_DEFAULT
  [11] TXRX_CONF_INV_CLK_PLL_TX — Invert PLL clock when the radio is in Tx mode
    0=TXRX_CONF_INV_CLK_PLL_TX_DISABLE; 1=TXRX_CONF_INV_CLK_PLL_TX_ENABLE
  [10] TXRX_CONF_INV_CLK_DIG_TX — Invert digital clock when the radio is in Tx mode
    0=TXRX_CONF_INV_CLK_DIG_TX_DISABLE; 1=TXRX_CONF_INV_CLK_DIG_TX_ENABLE
  [9:8] TXRX_CONF_SB_WAIT_T_TX — Xor value to apply to sb_wait_t (register SUBBAND_CONF) when the radio is in Tx mode
    0=TXRX_CONF_SB_WAIT_T_TX_DEFAULT
  [7] PA_RAMPUP_FULL_PA_RAMPUP — PA rampup configuration
    0=PA_RAMPUP_FULL_PA_RAMPUP_DISABLE (The PA rampup doesn't use the PA backoff enable bit); 1=PA_RAMPUP_FULL_PA_RAMPUP_ENABLE (The PA rampup uses the PA backoff enable bit (from -40 dBm))
  [6:4] PA_RAMPUP_DEL_PA_RAMPUP — Time to wait to start the ramp-up after the PA enable is detected
    4=PA_RAMPUP_DEL_PA_RAMPUP_DEFAULT
  [3:2] PA_RAMPUP_TAU_PA_RAMPUP — Time constant of the ramp-up/ramp-down
    0=PA_RAMPUP_TAU_PA_RAMPUP_DEFAULT
  [1] PA_RAMPUP_EN_PA_RAMPDOWN — PA ramp-down
    0=PA_RAMPUP_EN_PA_RAMPDOWN_DISABLE (Disable the PA ramp-down); 1=PA_RAMPUP_EN_PA_RAMPDOWN_ENABLE (Enable the PA ramp-down)
  [0] PA_RAMPUP_EN_PA_RAMPUP — PA ramp-up linearization
    0=PA_RAMPUP_EN_PA_RAMPUP_DISABLE (Disable the PA ramp-up); 1=PA_RAMPUP_EN_PA_RAMPUP_ENABLE (Enable the PA ramp-up)
